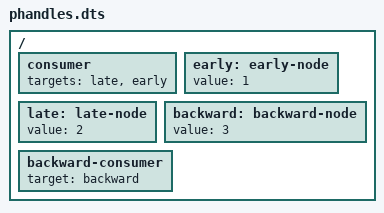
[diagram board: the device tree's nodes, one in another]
/dts-v1/;

/ {
    consumer {
        targets = <&late &early>;
    };

    early: early-node {
        value = <1>;
    };

    late: late-node {
        value = <2>;
    };

    backward: backward-node {
        value = <3>;
    };

    backward-consumer {
        target = <&backward>;
    };
};
